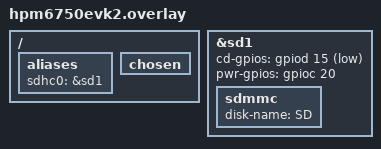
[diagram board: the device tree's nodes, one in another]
/*
* Copyright 2024-2026 HPMicro
* SPDX-License-Identifier: Apache-2.0
*/

/ {
aliases {
	sdhc0 = &sd1;
};

chosen {
};

};

&sd1 {
	status = "okay";
	cd-gpios = <&gpiod 15 ( GPIO_PULL_UP | GPIO_ACTIVE_LOW )>;
	pwr-gpios = <&gpioc 20 ( GPIO_PULL_UP | GPIO_ACTIVE_HIGH )>;
	sdmmc {
		disk-name = "SD";
		status = "okay";
	};
};
